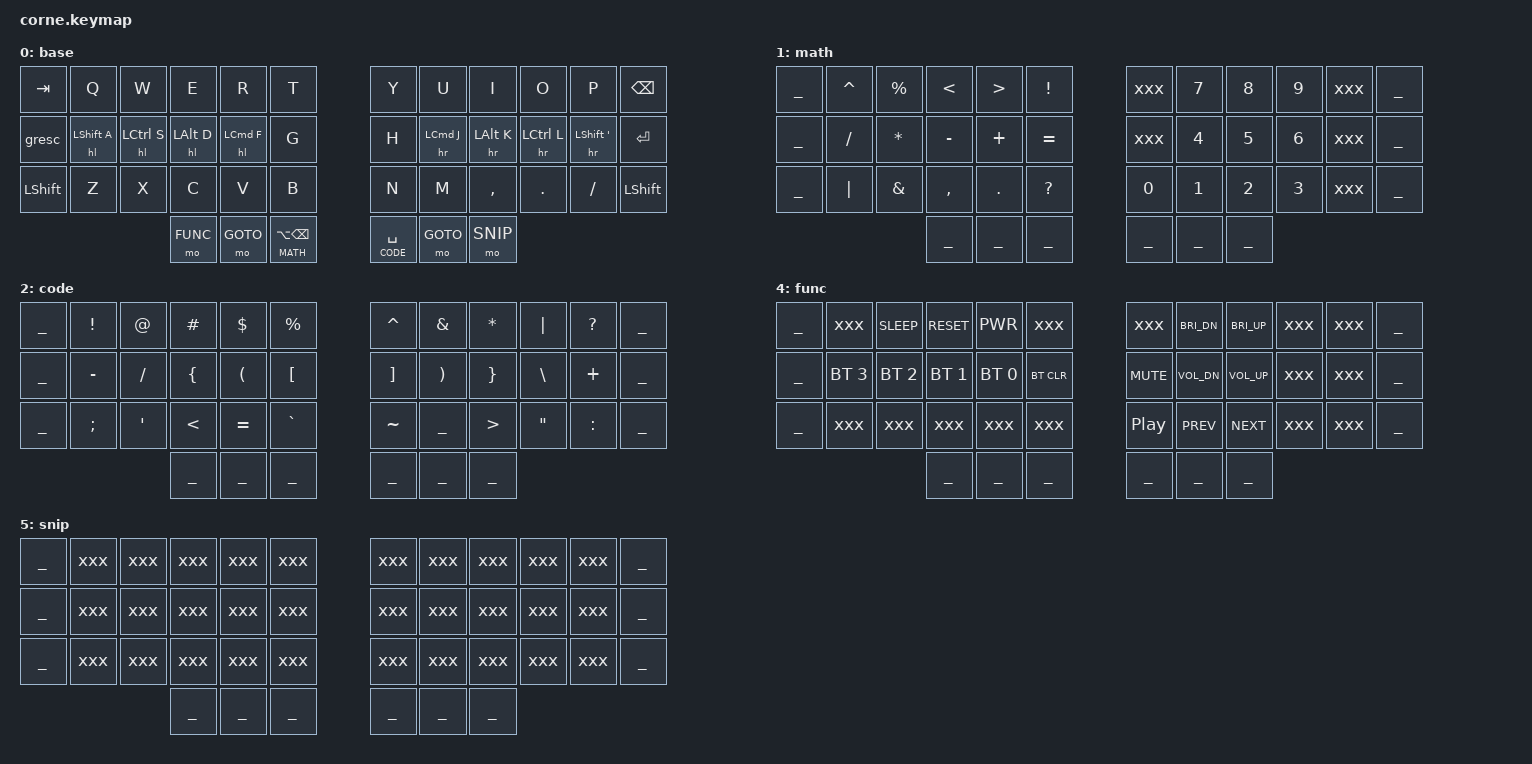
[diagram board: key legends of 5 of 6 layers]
/*
 * Copyright (c) 2020 The ZMK Contributors
 *
 * SPDX-License-Identifier: MIT
 */

#define ZMK_POINTING_DEFAULT_SCRL_VAL 20 

#define BASE  0
#define MATH  1
#define CODE  2
#define GOTO  3
#define FUNC  4
#define SNIP  5

#include <behaviors.dtsi>
#include <dt-bindings/zmk/keys.h>
#include <dt-bindings/zmk/bt.h>
#include <dt-bindings/zmk/pointing.h>
#include "helpers.h"

HOME_ROW_MOD(hl, &kp, &kp, KEYS_R THUMBS) // left home row mods
HOME_ROW_MOD(hr, &kp, &kp, KEYS_L THUMBS) // right home row mods

/ {
  behaviors {
    ltb: layer_tap_balanced {
      compatible = "zmk,behavior-hold-tap";
      #binding-cells = <2>;
      flavor = "balanced";
      tapping-term-ms = <280>;
      quick-tap-ms = <120>;
      bindings = <&mo>, <&kp>;
    };
  };
  combos {
    compatible = "zmk,combos";
    caps {
      timeout-ms = <100>;
      bindings = <&caps_word>;
      key-positions = <LM1 RM1>;
    };
    raycast {
      timeout-ms = <100>;
      bindings = <&kp LG(SPACE)>;
      key-positions = <LH0 RH0>;
    };
  };
  macros {
    tm: tm {
      compatible = "zmk,behavior-macro-one-param";
      #binding-cells = <1>;
      bindings = <&macro_tap &kp GRAVE>, <&macro_param_1to1>, <&macro_tap &kp MACRO_PLACEHOLDER>;
    };
  };
  keymap {
    compatible = "zmk,keymap";
    base {
      bindings = <
        &kp TAB    &kp Q        &kp W        &kp E       &kp R       &kp T               &kp Y            &kp U       &kp I       &kp O        &kp P          &kp BSPC
        &gresc     &hl LSHFT A  &hl LCTRL S  &hl LALT D  &hl LCMD F  &kp G               &kp H            &hr LCMD J  &hr LALT K  &hr LCTRL L  &hr LSHFT SQT  &kp ENTER
        &kp LSHFT  &kp Z        &kp X        &kp C       &kp V       &kp B               &kp N            &kp M       &kp COMMA   &kp DOT      &kp FSLH       &kp LSHFT
                                             &mo FUNC    &mo GOTO    &ltb MATH LA(BSPC)  &ltb CODE SPACE  &mo GOTO    &mo SNIP
      >;
      label = "base";
    };
    math {
      bindings = <
        ___  &kp CARET &kp PRCNT  &kp LT     &kp GT    &kp EXCL   xxx     &kp N7  &kp N8  &kp N9  xxx  ___
        ___  &kp FSLH  &kp STAR   &kp MINUS  &kp PLUS  &kp EQUAL  xxx     &kp N4  &kp N5  &kp N6  xxx  ___
        ___  &kp PIPE  &kp AMPS   &kp COMMA  &kp DOT   &kp QMARK  &kp N0  &kp N1  &kp N2  &kp N3  xxx  ___
                                  ___        ___       ___        ___     ___     ___
      >;
      label = "math";
    };
    code {
      bindings = <
        ___  &kp EXCL   &kp AT    &kp HASH  &kp DLLR   &kp PRCNT  &kp CARET  &kp AMPS   &kp STAR  &kp PIPE  &kp QMARK  ___
        ___  &kp MINUS  &kp FSLH  &kp LBRC  &kp LPAR   &kp LBKT   &kp RBKT   &kp RPAR   &kp RBRC  &kp BSLH  &kp PLUS   ___
        ___  &kp SEMI   &kp SQT   &kp LT    &kp EQUAL  &kp GRAVE  &kp TILDE  &kp UNDER  &kp GT    &kp DQT   &kp COLON  ___
                                  ___       ___        ___        ___        ___        ___
      >;
      label = "code";
    };
    goto {
      bindings = <
        ___  &tm N4  &tm N3  &tm N2  &tm N1  xxx  xxx       &kp LA(N1)            &kp LA(N2)             &kp LA(N3)             &kp LA(N4)      ___
        ___  &tm N8  &tm N7  &tm N6  &tm N8  xxx  &kp LEFT  &kp DOWN              &kp UP                 &kp RIGHT              &msc SCRL_DOWN  ___
        ___  xxx     xxx     &tm P   &tm N   xxx  xxx       &kp LG(LA(LC(LEFT)))  &kp LG(LA(LC(ENTER)))  &kp LG(LA(LC(RIGHT)))  &msc SCRL_UP    ___
                             ___     ___     ___  ___       ___                   ___
      >;
      label = "goto";
    };
    func {
      bindings = <
        ___  xxx           &kp C_SLEEP   &kp C_RESET   &kp C_PWR     xxx         xxx         &kp C_BRI_DN  &kp C_BRI_UP  xxx  xxx  ___     
        ___  &bt BT_SEL 3  &bt BT_SEL 2  &bt BT_SEL 1  &bt BT_SEL 0  &bt BT_CLR  &kp C_MUTE  &kp C_VOL_DN  &kp C_VOL_UP  xxx  xxx  ___
        ___  xxx           xxx           xxx           xxx           xxx         &kp C_PP    &kp C_PREV    &kp C_NEXT    xxx  xxx  ___
                                         ___           ___           ___         ___  ___  ___
      >;
      label = "func";
    };
    snip {
      bindings = <
        ___  xxx  xxx  xxx  xxx  xxx  xxx  xxx  xxx  xxx  xxx  ___     
        ___  xxx  xxx  xxx  xxx  xxx  xxx  xxx  xxx  xxx  xxx  ___
        ___  xxx  xxx  xxx  xxx  xxx  xxx  xxx  xxx  xxx  xxx  ___
                       ___  ___  ___  ___  ___  ___
      >;
      label = "snip";
    };
  };
};
